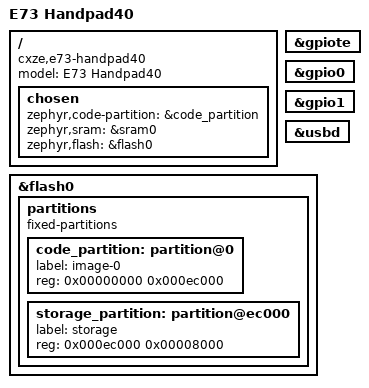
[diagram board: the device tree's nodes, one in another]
/dts-v1/;
#include <nordic/nrf52840_qiaa.dtsi>

/ {
    model = "E73 Handpad40";
    compatible = "cxze,e73-handpad40";

    chosen {
        zephyr,code-partition = &code_partition;
        zephyr,sram = &sram0;
        zephyr,flash = &flash0;
    };
};

&gpiote {
    status = "okay";
};

&gpio0 {
    status = "okay";
};

&gpio1 {
    status = "okay";
};

zephyr_udc0: &usbd {
    status = "okay";
};

&flash0 {
    partitions {
        compatible = "fixed-partitions";
        #address-cells = <1>;
        #size-cells = <1>;

        code_partition: partition@0 {
            label = "image-0";
            reg = <0x00000000 0x000ec000>;
        };

        storage_partition: partition@ec000 {
            label = "storage";
            reg = <0x000ec000 0x00008000>;
        };
    };
};
